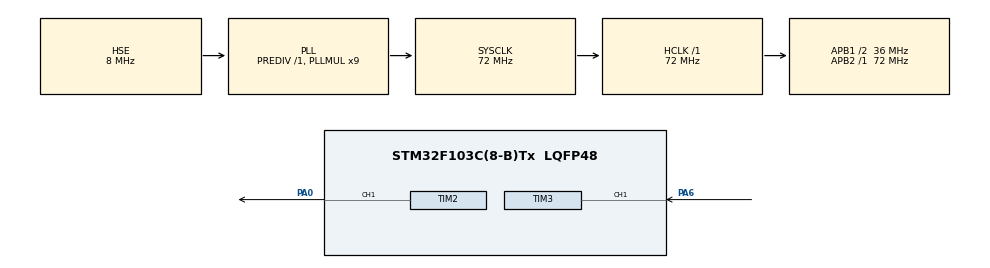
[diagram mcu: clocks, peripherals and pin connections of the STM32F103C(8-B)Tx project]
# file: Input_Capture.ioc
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Mcu.Family=STM32F1
Mcu.Name=STM32F103C(8-B)Tx
Mcu.Package=LQFP48
NVIC.PriorityGroup=NVIC_PRIORITYGROUP_4
NVIC.TIM3_IRQn=true\:0\:0\:false\:false\:true\:true\:true\:true
PA0-WKUP.Signal=S_TIM2_CH1_ETR
PA13.Mode=Serial_Wire
PA13.Signal=SYS_JTMS-SWDIO
PA14.Mode=Serial_Wire
PA14.Signal=SYS_JTCK-SWCLK
PA6.Signal=S_TIM3_CH1
PD0-OSC_IN.Mode=HSE-External-Oscillator
PD0-OSC_IN.Signal=RCC_OSC_IN
PD1-OSC_OUT.Mode=HSE-External-Oscillator
PD1-OSC_OUT.Signal=RCC_OSC_OUT
ProjectManager.HeapSize=0x200
ProjectManager.StackSize=0x400
ProjectManager.TargetToolchain=MDK-ARM V5.32
RCC.AHBFreq_Value=72000000
RCC.APB1CLKDivider=RCC_HCLK_DIV2
RCC.APB1Freq_Value=36000000
RCC.APB1TimFreq_Value=72000000
RCC.APB2Freq_Value=72000000
RCC.APB2TimFreq_Value=72000000
RCC.HCLKFreq_Value=72000000
RCC.PLLMUL=RCC_PLL_MUL9
RCC.PLLSourceVirtual=RCC_PLLSOURCE_HSE
RCC.SYSCLKFreq_VALUE=72000000
RCC.SYSCLKSource=RCC_SYSCLKSOURCE_PLLCLK
RCC.USBFreq_Value=72000000
SH.S_TIM2_CH1_ETR.0=TIM2_CH1,PWM Generation1 CH1
SH.S_TIM3_CH1.0=TIM3_CH1,Input_Capture1_from_TI1
TIM2.Channel-PWM\ Generation1\ CH1=TIM_CHANNEL_1
TIM2.Period=1000-1
TIM2.Prescaler=72-1
TIM2.Pulse-PWM\ Generation1\ CH1=250
TIM3.Channel-Input_Capture1_from_TI1=TIM_CHANNEL_1
TIM3.Prescaler=72-1
VP_TIM2_VS_ClockSourceINT.Mode=Internal
VP_TIM3_VS_ClockSourceINT.Mode=Internal
board=custom

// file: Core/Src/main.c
/* USER CODE BEGIN Header */
/**
  ******************************************************************************
  * @file           : main.c
  * @brief          : Main program body
  ******************************************************************************
  * @attention
  *
  * Copyright (c) 2026 STMicroelectronics.
  * All rights reserved.
  *
  * This software is licensed under terms that can be found in the LICENSE file
  * in the root directory of this software component.
  * If no LICENSE file comes with this software, it is provided AS-IS.
  *
  ******************************************************************************
  */
/* USER CODE END Header */
#include "main.h"
#include "tim.h"
#include "gpio.h"

/* USER CODE BEGIN Includes */
#define IC_COUNT_FREQ_HZ 1000000	//定时器的计数频率
/* USER CODE END Includes */

/* USER CODE BEGIN PV */
volatile uint8_t capture_state = 0;	//捕获状态标志位
volatile uint32_t rise_value1 = 0;	//上升沿捕获值1
volatile uint32_t fall_value = 0;	//下降沿捕获值
volatile uint32_t rise_value2 = 0;	//上升沿捕获值2
volatile uint32_t high_counts = 0;	//高电平计数值
volatile uint32_t period_counts = 0;	//周期计数值
volatile float duty = 0.0f;	//占空比
volatile float fre = 0.0f;	//频率
/* USER CODE END PV */

void SystemClock_Config(void);

int main(void)
{

  /* MCU Configuration--------------------------------------------------------*/

  /* Reset of all peripherals, Initializes the Flash interface and the Systick. */
  HAL_Init();

  /* Configure the system clock */
  SystemClock_Config();

  /* Initialize all configured peripherals */
  MX_GPIO_Init();
  MX_TIM2_Init();
  MX_TIM3_Init();
  /* USER CODE BEGIN 2 */
	HAL_TIM_PWM_Start(&htim2, TIM_CHANNEL_1);	//启动TIM2PWM输出
	HAL_TIM_IC_Start_IT(&htim3, TIM_CHANNEL_1);	//启动TIM3输入捕获并使能中断
  /* USER CODE END 2 */

  /* Infinite loop */
  /* USER CODE BEGIN WHILE */
  while (1)
  {
		TIM2->CCR1 = 250;
		HAL_Delay(2000);
		TIM2->CCR1 = 500;
		HAL_Delay(2000);
		TIM2->CCR1 = 750;
		HAL_Delay(2000);

    /* USER CODE END WHILE */

  }
}

void SystemClock_Config(void)
{
  RCC_OscInitTypeDef RCC_OscInitStruct = {0};
  RCC_ClkInitTypeDef RCC_ClkInitStruct = {0};

  /** Initializes the RCC Oscillators according to the specified parameters
  * in the RCC_OscInitTypeDef structure.
  */
  RCC_OscInitStruct.OscillatorType = RCC_OSCILLATORTYPE_HSE;
  RCC_OscInitStruct.HSEState = RCC_HSE_ON;
  RCC_OscInitStruct.HSEPredivValue = RCC_HSE_PREDIV_DIV1;
  RCC_OscInitStruct.HSIState = RCC_HSI_ON;
  RCC_OscInitStruct.PLL.PLLState = RCC_PLL_ON;
  RCC_OscInitStruct.PLL.PLLSource = RCC_PLLSOURCE_HSE;
  RCC_OscInitStruct.PLL.PLLMUL = RCC_PLL_MUL9;
  if (HAL_RCC_OscConfig(&RCC_OscInitStruct) != HAL_OK)
  {
    Error_Handler();
  }

  /** Initializes the CPU, AHB and APB buses clocks
  */
  RCC_ClkInitStruct.ClockType = RCC_CLOCKTYPE_HCLK|RCC_CLOCKTYPE_SYSCLK
                              |RCC_CLOCKTYPE_PCLK1|RCC_CLOCKTYPE_PCLK2;
  RCC_ClkInitStruct.SYSCLKSource = RCC_SYSCLKSOURCE_PLLCLK;
  RCC_ClkInitStruct.AHBCLKDivider = RCC_SYSCLK_DIV1;
  RCC_ClkInitStruct.APB1CLKDivider = RCC_HCLK_DIV2;
  RCC_ClkInitStruct.APB2CLKDivider = RCC_HCLK_DIV1;

  if (HAL_RCC_ClockConfig(&RCC_ClkInitStruct, FLASH_LATENCY_2) != HAL_OK)
  {
    Error_Handler();
  }
}

/* USER CODE BEGIN 4 */
void HAL_TIM_IC_CaptureCallback(TIM_HandleTypeDef *htim)	//TIM3输入捕获中断回调函数
{
	if(htim->Instance == TIM3)	//判断中断来源
	{
		uint32_t now_value = HAL_TIM_ReadCapturedValue(htim, TIM_CHANNEL_1);//读取捕获值

		switch(capture_state)//捕获状态选择
		{
			case 0 : //未进行捕获时
				rise_value1 = now_value;//保存第一次上升沿捕获值
				__HAL_TIM_SET_CAPTUREPOLARITY(htim, TIM_CHANNEL_1, TIM_INPUTCHANNELPOLARITY_FALLING);//极性切换到下降沿捕获
				capture_state = 1;//更新捕获状态
				break;
			case 1 : //已经进行一次上升沿捕获
				fall_value = now_value;//保存下降沿捕获值
				__HAL_TIM_SET_CAPTUREPOLARITY(htim, TIM_CHANNEL_1, TIM_INPUTCHANNELPOLARITY_RISING);//极性切换到上升沿捕获
				high_counts = fall_value - rise_value1;//计算高电平计数值
				capture_state = 2;//更新状态
				break;
			case 2 : //已经进行下降沿捕获
				rise_value2 = now_value;//保存第二次上升沿捕获值
				period_counts = rise_value2 - rise_value1;//计算周期计数值
				duty = (float)high_counts / period_counts;//计算占空比
				fre = IC_COUNT_FREQ_HZ / (float)period_counts;
				capture_state = 0;//更新状态
				break;
		}
	}
}
/* USER CODE END 4 */

void Error_Handler(void)
{
  __disable_irq();
  while (1)
  {
  }
}
